# LargeDummyDevice register map
File version: 1.0
Registers are 32-bit, read-write, no defined reset value unless marked. A register's access mark holds for its fields unless they carry their own. Offsets are from the block's base; [hi:lo] are bit positions.

## PERIPHERAL_14
Base 0x4000D000
0x04 REG_1 — Register 1
  [11] FIELD_1, [14:11] FIELD_2, [8:6] FIELD_3
0x08 REG_2 — Register 2
  [28:26] FIELD_7, [25:21] FIELD_4, [22:18] FIELD_3, [21:17] FIELD_5, [15:13] FIELD_1, [6:4] FIELD_6, [3:2] FIELD_2, [4:0] FIELD_8
0x0C REG_3 — Register 3
  [29:26] FIELD_3, [22:20] FIELD_2, [20:18] FIELD_1, [11:10] FIELD_4
0x10 REG_4 — Register 4
  [30] FIELD_1, [31:29] FIELD_8, [26:25] FIELD_9, [24:22] FIELD_2, [24:22] FIELD_6, [24:21] FIELD_4, [19:18] FIELD_7, [17:13] FIELD_14, [15:12] FIELD_11, [13:10] FIELD_13, [9:8] FIELD_5, [10:7] FIELD_3, [5:4] FIELD_12, [5:1] FIELD_10
0x14 REG_5 — Register 5
  [31] FIELD_4, [34:30] FIELD_25, [30:28] FIELD_26, [30:27] FIELD_24, [24] FIELD_23, [24:23] FIELD_21, [24:22] FIELD_3, [25:22] FIELD_13, [25:22] FIELD_16, [24:20] FIELD_15, [21:19] FIELD_14, [22:18] FIELD_2, [19:17] FIELD_5, [21:17] FIELD_11, [18:16] FIELD_12, [11:10] FIELD_6, [10:8] FIELD_18, [11:8] FIELD_20, [11:7] FIELD_7, [10:7] FIELD_8, [10:7] FIELD_19, [7:4] FIELD_22, [4:2] FIELD_1, [3:2] FIELD_10, [4:1] FIELD_17, [0] FIELD_9
0x18 REG_6 — Register 6
  [33:31] FIELD_30, [31:30] FIELD_9, [26] FIELD_11, [28:26] FIELD_18, [27:24] FIELD_8, [28:24] FIELD_16, [25:24] FIELD_24, [26:22] FIELD_5, [23:22] FIELD_19, [24:22] FIELD_28, [23:20] FIELD_1, [21:20] FIELD_22, [17] FIELD_20, [17] FIELD_25, [20:16] FIELD_13, [16:15] FIELD_7, [15:13] FIELD_21, [9:8] FIELD_10, [8] FIELD_14, [10:8] FIELD_15, [9:8] FIELD_27, [8:7] FIELD_3, [7] FIELD_6, [6] FIELD_29, [5] FIELD_2, [7:3] FIELD_17, [3:2] FIELD_23, [4:1] FIELD_4, [5:1] FIELD_12, [1] FIELD_26
0x1C REG_7 — Register 7
  [33:31] FIELD_17, [34:31] FIELD_28, [32:29] FIELD_11, [30:29] FIELD_20, [30:29] FIELD_23, [29:28] FIELD_10, [31:28] FIELD_32, [29:26] FIELD_1, [29:26] FIELD_12, [29:26] FIELD_14, [27:25] FIELD_6, [24:23] FIELD_24, [22:21] FIELD_22, [20:19] FIELD_18, [22:19] FIELD_19, [22:18] FIELD_13, [20:18] FIELD_15, [19:15] FIELD_5, [16:13] FIELD_2, [17:13] FIELD_27, [12:11] FIELD_4, [12:11] FIELD_7, [14:11] FIELD_30, [10:8] FIELD_9, [12:8] FIELD_31, [10:6] FIELD_25, [6:5] FIELD_3, [5:4] FIELD_8, [5:1] FIELD_16, [1] FIELD_21, [1:0] FIELD_26, [0] FIELD_29
0x20 REG_8 — Register 8
  [33:30] FIELD_4, [26:23] FIELD_3, [25:21] FIELD_2, [15:14] FIELD_5, [16:12] FIELD_1, [9:7] FIELD_6, [4:2] FIELD_7, [2] FIELD_8
0x24 REG_9 — Register 9
  [31] FIELD_5, [32:29] FIELD_6, [31:29] FIELD_26, [31:28] FIELD_7, [27:24] FIELD_11, [22] FIELD_19, [25:21] FIELD_20, [22:20] FIELD_17, [17:16] FIELD_4, [19:16] FIELD_14, [18:15] FIELD_13, [17:15] FIELD_30, [14] FIELD_1, [18:14] FIELD_16, [16:13] FIELD_15, [17:13] FIELD_27, [15:13] FIELD_29, [14:12] FIELD_22, [16:12] FIELD_24, [16:12] FIELD_28, [11:10] FIELD_25, [10:8] FIELD_10, [11:7] FIELD_21, [8:6] FIELD_3, [7:6] FIELD_18, [5] FIELD_9, [6:4] FIELD_2, [5:3] FIELD_12, [5:3] FIELD_23, [2:1] FIELD_8
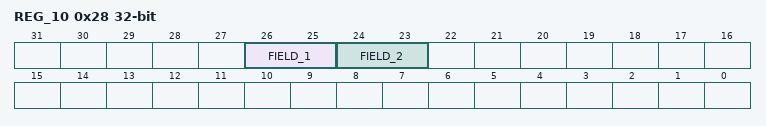
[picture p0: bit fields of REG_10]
0x28 REG_10 — Register 10
  [26:25] FIELD_1, [24:23] FIELD_2
0x2C REG_11 — Register 11
  [32:31] FIELD_20, [34:30] FIELD_9, [32:28] FIELD_14, [27] FIELD_4, [27:25] FIELD_13, [25:24] FIELD_1, [26:22] FIELD_3, [25:22] FIELD_18, [15:13] FIELD_12, [13:12] FIELD_6, [14:10] FIELD_5, [11:10] FIELD_7, [11:10] FIELD_19, [9] FIELD_10, [9:5] FIELD_15, [6:4] FIELD_2, [5:3] FIELD_11, [4:3] FIELD_16, [6:3] FIELD_17, [5:1] FIELD_8
0x30 REG_12 — Register 12
  [34:31] FIELD_14, [25:21] FIELD_1, [22:20] FIELD_6, [18:17] FIELD_3, [16] FIELD_15, [17:14] FIELD_12, [16:12] FIELD_2, [13:11] FIELD_8, [10:7] FIELD_10, [11:7] FIELD_13, [7:6] FIELD_5, [5:2] FIELD_4, [3:2] FIELD_11, [2:0] FIELD_7, [0] FIELD_9
0x34 REG_13 — Register 13
  [30] FIELD_11, [31:30] FIELD_16, [30:29] FIELD_6, [31:29] FIELD_21, [29:28] FIELD_13, [27:26] FIELD_9, [28:25] FIELD_4, [25:24] FIELD_19, [23:20] FIELD_10, [22:19] FIELD_7, [19:18] FIELD_25, [16] FIELD_22, [18:14] FIELD_1, [18:14] FIELD_5, [13] FIELD_15, [13:12] FIELD_24, [15:11] FIELD_8, [12:11] FIELD_23, [10:6] FIELD_27, [8:5] FIELD_2, [9:5] FIELD_17, [7:5] FIELD_18, [5:4] FIELD_3, [8:4] FIELD_26, [6:3] FIELD_20, [1] FIELD_14, [1:0] FIELD_12
0x38 REG_14 — Register 14
  [32:30] FIELD_6, [28:26] FIELD_5, [11:8] FIELD_1, [9:8] FIELD_4, [7:6] FIELD_3, [9:5] FIELD_2
0x3C REG_15 — Register 15
  [30:29] FIELD_1, [32:28] FIELD_2, [30:27] FIELD_6, [23:19] FIELD_4, [16:15] FIELD_3, [17:15] FIELD_8, [10:9] FIELD_5, [4:0] FIELD_7
0x40 REG_16 — Register 16
  [31:29] FIELD_4, [32:29] FIELD_17, [29:28] FIELD_16, [26] FIELD_2, [28:25] FIELD_19, [24:20] FIELD_7, [23:20] FIELD_18, [19] FIELD_20, [16:15] FIELD_6, [19:15] FIELD_9, [13] FIELD_12, [15:12] FIELD_10, [13:12] FIELD_13, [13:12] FIELD_14, [11:7] FIELD_1, [7:6] FIELD_8, [8:4] FIELD_5, [4:1] FIELD_11, [4:1] FIELD_15, [2:0] FIELD_3
0x44 REG_17 — Register 17
  [30:29] FIELD_4, [25:24] FIELD_6, [24:23] FIELD_2, [25:21] FIELD_3, [21] FIELD_10, [17:14] FIELD_1, [12] FIELD_7, [13:10] FIELD_9, [11:10] FIELD_12, [13:10] FIELD_14, [11:9] FIELD_8, [11:8] FIELD_5, [10:8] FIELD_13, [6] FIELD_11
0x48 REG_18 — Register 18
  [33:30] FIELD_7, [32:29] FIELD_26, [30:26] FIELD_9, [26] FIELD_31, [28:25] FIELD_24, [26:24] FIELD_4, [24:22] FIELD_21, [25:22] FIELD_27, [21:18] FIELD_20, [20:18] FIELD_25, [21:18] FIELD_28, [21:17] FIELD_17, [17:16] FIELD_6, [16:15] FIELD_11, [18:14] FIELD_29, [16:12] FIELD_18, [13:11] FIELD_23, [13:10] FIELD_3, [10:9] FIELD_15, [11:7] FIELD_10, [7] FIELD_19, [10:6] FIELD_16, [8:5] FIELD_30, [5:3] FIELD_5, [4:3] FIELD_8, [5:3] FIELD_22, [4:2] FIELD_1, [4:1] FIELD_13, [2:1] FIELD_14, [0] FIELD_2, [4:0] FIELD_12
0x4C REG_19 — Register 19
  [30:29] FIELD_4, [29] FIELD_15, [32:29] FIELD_28, [29:26] FIELD_1, [29:26] FIELD_11, [25] FIELD_18, [29:25] FIELD_22, [28:24] FIELD_24, [25:22] FIELD_30, [22:21] FIELD_27, [24:20] FIELD_19, [21:18] FIELD_21, [17] FIELD_26, [19:16] FIELD_20, [17:15] FIELD_13, [16:14] FIELD_9, [16:12] FIELD_29, [14:12] FIELD_32, [13:11] FIELD_7, [11] FIELD_16, [12:11] FIELD_23, [10] FIELD_8, [13:10] FIELD_14, [11:8] FIELD_31, [7] FIELD_10, [11:7] FIELD_12, [9:7] FIELD_25, [7:6] FIELD_3, [4:2] FIELD_5, [3:2] FIELD_6, [4:1] FIELD_2, [0] FIELD_17
0x50 REG_20 — Register 20
  [25:24] FIELD_3, [25:23] FIELD_10, [22:20] FIELD_8, [14:11] FIELD_11, [14:10] FIELD_7, [9:8] FIELD_1, [8] FIELD_4, [11:7] FIELD_9, [6] FIELD_2, [9:5] FIELD_6, [2:1] FIELD_5
0x54 REG_21 — Register 21
  [26:24] FIELD_4, [24] FIELD_8, [23:22] FIELD_2, [23:21] FIELD_1, [15:12] FIELD_7, [7] FIELD_5, [5] FIELD_3, [5:3] FIELD_6, [6:3] FIELD_9
